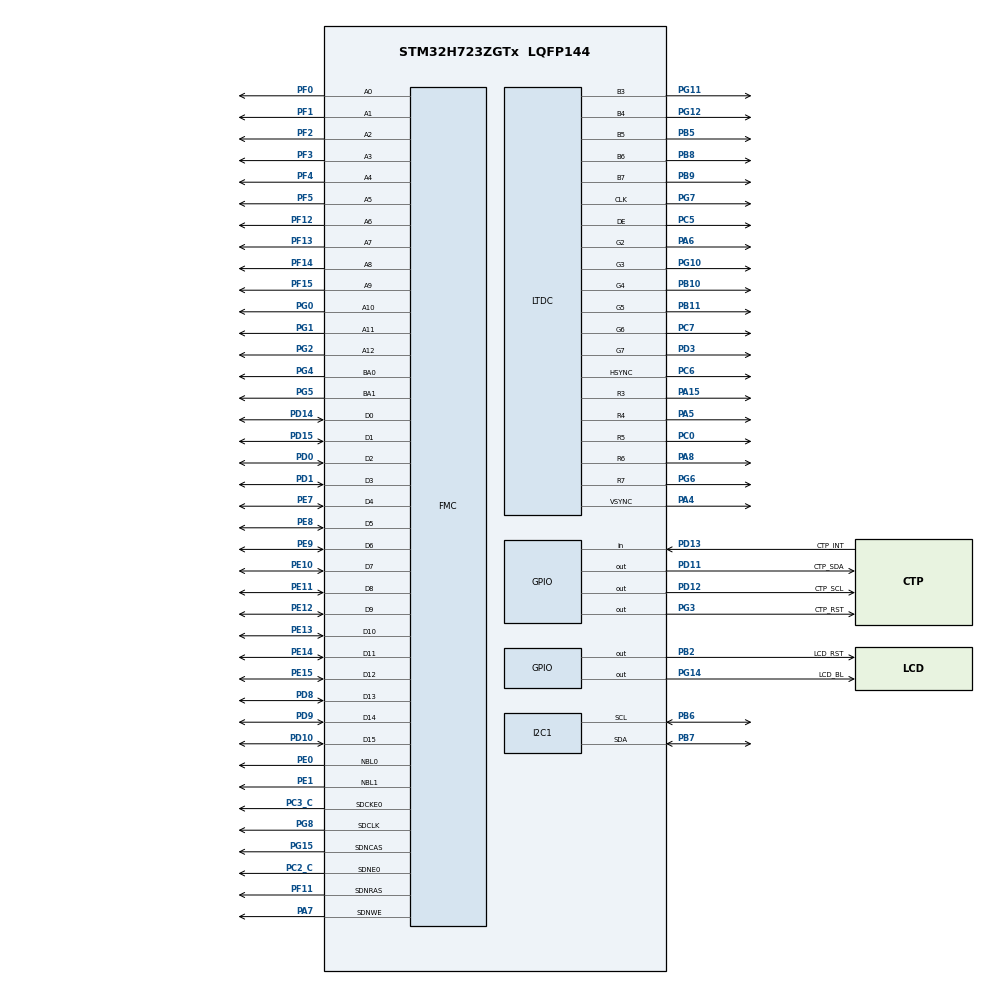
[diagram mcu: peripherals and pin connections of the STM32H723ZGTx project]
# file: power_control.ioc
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CORTEX_M7.AccessPermission-Cortex_Memory_Protection_Unit_Region0_Settings=MPU_REGION_NO_ACCESS
CORTEX_M7.AccessPermission-Cortex_Memory_Protection_Unit_Region1_Settings=MPU_REGION_FULL_ACCESS
CORTEX_M7.BaseAddress-Cortex_Memory_Protection_Unit_Region0_Settings=0x0
CORTEX_M7.BaseAddress-Cortex_Memory_Protection_Unit_Region1_Settings=0xC0000000
CORTEX_M7.DisableExec-Cortex_Memory_Protection_Unit_Region0_Settings=MPU_INSTRUCTION_ACCESS_DISABLE
CORTEX_M7.DisableExec-Cortex_Memory_Protection_Unit_Region1_Settings=MPU_INSTRUCTION_ACCESS_DISABLE
CORTEX_M7.Enable-Cortex_Memory_Protection_Unit_Region0_Settings=MPU_REGION_ENABLE
CORTEX_M7.Enable-Cortex_Memory_Protection_Unit_Region1_Settings=MPU_REGION_ENABLE
CORTEX_M7.IsBufferable-Cortex_Memory_Protection_Unit_Region0_Settings=MPU_ACCESS_NOT_BUFFERABLE
CORTEX_M7.IsBufferable-Cortex_Memory_Protection_Unit_Region1_Settings=MPU_ACCESS_NOT_BUFFERABLE
CORTEX_M7.IsCacheable-Cortex_Memory_Protection_Unit_Region0_Settings=MPU_ACCESS_NOT_CACHEABLE
CORTEX_M7.IsCacheable-Cortex_Memory_Protection_Unit_Region1_Settings=MPU_ACCESS_NOT_CACHEABLE
CORTEX_M7.IsShareable-Cortex_Memory_Protection_Unit_Region0_Settings=MPU_ACCESS_SHAREABLE
CORTEX_M7.IsShareable-Cortex_Memory_Protection_Unit_Region1_Settings=MPU_ACCESS_NOT_SHAREABLE
CORTEX_M7.MPU_Control=MPU_PRIVILEGED_DEFAULT
CORTEX_M7.Size-Cortex_Memory_Protection_Unit_Region0_Settings=MPU_REGION_SIZE_4GB
CORTEX_M7.Size-Cortex_Memory_Protection_Unit_Region1_Settings=MPU_REGION_SIZE_32MB
CORTEX_M7.SubRegionDisable-Cortex_Memory_Protection_Unit_Region0_Settings=0x87
CORTEX_M7.SubRegionDisable-Cortex_Memory_Protection_Unit_Region1_Settings=0x00
CORTEX_M7.TypeExtField-Cortex_Memory_Protection_Unit_Region0_Settings=MPU_TEX_LEVEL0
CORTEX_M7.TypeExtField-Cortex_Memory_Protection_Unit_Region1_Settings=MPU_TEX_LEVEL1
CORTEX_M7.default_mode_Activation=1
FMC.CASLatency1=FMC_SDRAM_CAS_LATENCY_2
FMC.ColumnBitsNumber1=FMC_SDRAM_COLUMN_BITS_NUM_9
FMC.ExitSelfRefreshDelay1=8
FMC.LoadToActiveDelay1=2
FMC.RCDDelay1=2
FMC.RPDelay1=2
FMC.ReadBurst1=FMC_SDRAM_RBURST_ENABLE
FMC.ReadPipeDelay1=FMC_SDRAM_RPIPE_DELAY_1
FMC.RowCycleDelay1=7
FMC.SDClockPeriod1=FMC_SDRAM_CLOCK_PERIOD_2
FMC.SelfRefreshTime1=7
FMC.WriteRecoveryTime1=5
FREERTOS.Tasks01=defaultTask,24,128,StartDefaultTask,Default,NULL,Dynamic,NULL,NULL;lcd_task,24,1024,start_lcd_task,As weak,NULL,Dynamic,NULL,NULL
FREERTOS.configRECORD_STACK_HIGH_ADDRESS=1
FREERTOS.configUSE_STATS_FORMATTING_FUNCTIONS=1
I2C1.Timing=0x60404E72
LTDC.ActiveW=800
LTDC.Alpha_L0=255
LTDC.FBStartAdress_L0=0xC0000000
LTDC.HBP=88
LTDC.HFP=40
LTDC.HSync=48
LTDC.ImageHeight_L0=480
LTDC.ImageWidth_L0=800
LTDC.Layers=0
LTDC.PixelFormat_L0=LTDC_PIXEL_FORMAT_RGB565
LTDC.VBP=32
LTDC.VFP=13
LTDC.VSync=3
LTDC.WindowX1_L0=800
LTDC.WindowY1_L0=480
Mcu.Family=STM32H7
Mcu.Name=STM32H723ZGTx
Mcu.Package=LQFP144
NVIC.PriorityGroup=NVIC_PRIORITYGROUP_4
NVIC.TIM4_IRQn=true\:15\:0\:false\:false\:true\:false\:false\:true\:true
NVIC.TimeBase=TIM4_IRQn
NVIC.TimeBaseIP=TIM4
PA13(JTMS/SWDIO).Mode=Serial_Wire
PA13(JTMS/SWDIO).Signal=DEBUG_JTMS-SWDIO
PA14(JTCK/SWCLK).Mode=Serial_Wire
PA14(JTCK/SWCLK).Signal=DEBUG_JTCK-SWCLK
PA15(JTDI).GPIO_Speed=GPIO_SPEED_FREQ_VERY_HIGH
PA15(JTDI).Mode=RGB565
PA15(JTDI).Signal=LTDC_R3
PA4.GPIO_Speed=GPIO_SPEED_FREQ_VERY_HIGH
PA4.Mode=RGB565
PA4.Signal=LTDC_VSYNC
PA5.GPIO_Speed=GPIO_SPEED_FREQ_VERY_HIGH
PA5.Mode=RGB565
PA5.Signal=LTDC_R4
PA6.GPIO_Speed=GPIO_SPEED_FREQ_VERY_HIGH
PA6.Mode=RGB565
PA6.Signal=LTDC_G2
PA7.Signal=FMC_SDNWE
PA8.GPIO_Speed=GPIO_SPEED_FREQ_VERY_HIGH
PA8.Mode=RGB565
PA8.Signal=LTDC_R6
PB10.GPIO_Speed=GPIO_SPEED_FREQ_VERY_HIGH
PB10.Mode=RGB565
PB10.Signal=LTDC_G4
PB11.GPIO_Speed=GPIO_SPEED_FREQ_VERY_HIGH
PB11.Mode=RGB565
PB11.Signal=LTDC_G5
PB2.GPIO_Label=LCD_RST
PB2.GPIO_Speed=GPIO_SPEED_FREQ_LOW
PB2.PinState=GPIO_PIN_SET
PB2.Signal=GPIO_Output
PB5.GPIO_Speed=GPIO_SPEED_FREQ_VERY_HIGH
PB5.Mode=RGB565
PB5.Signal=LTDC_B5
PB6.Mode=I2C
PB6.Signal=I2C1_SCL
PB7.Mode=I2C
PB7.Signal=I2C1_SDA
PB8.GPIO_Speed=GPIO_SPEED_FREQ_VERY_HIGH
PB8.Mode=RGB565
PB8.Signal=LTDC_B6
PB9.GPIO_Speed=GPIO_SPEED_FREQ_VERY_HIGH
PB9.Mode=RGB565
PB9.Signal=LTDC_B7
PC0.GPIO_Speed=GPIO_SPEED_FREQ_VERY_HIGH
PC0.Mode=RGB565
PC0.Signal=LTDC_R5
PC2_C.Mode=SdramChipSelect1_1
PC2_C.Signal=FMC_SDNE0
PC3_C.Mode=SdramChipSelect1_1
PC3_C.Signal=FMC_SDCKE0
PC5.GPIO_Speed=GPIO_SPEED_FREQ_VERY_HIGH
PC5.Mode=RGB565
PC5.Signal=LTDC_DE
PC6.GPIO_Speed=GPIO_SPEED_FREQ_VERY_HIGH
PC6.Mode=RGB565
PC6.Signal=LTDC_HSYNC
PC7.GPIO_Speed=GPIO_SPEED_FREQ_VERY_HIGH
PC7.Mode=RGB565
PC7.Signal=LTDC_G6
PD0.Signal=FMC_D2_DA2
PD1.Signal=FMC_D3_DA3
PD10.Signal=FMC_D15_DA15
PD11.GPIO_Label=CTP_SDA
PD11.GPIO_ModeDefaultOutputPP=GPIO_MODE_OUTPUT_OD
PD11.GPIO_PuPd=GPIO_NOPULL
PD11.GPIO_Speed=GPIO_SPEED_FREQ_VERY_HIGH
PD11.PinState=GPIO_PIN_SET
PD11.Signal=GPIO_Output
PD12.GPIO_Label=CTP_SCL
PD12.GPIO_ModeDefaultOutputPP=GPIO_MODE_OUTPUT_OD
PD12.GPIO_PuPd=GPIO_NOPULL
PD12.GPIO_Speed=GPIO_SPEED_FREQ_VERY_HIGH
PD12.PinState=GPIO_PIN_SET
PD12.Signal=GPIO_Output
PD13.GPIO_Label=CTP_INT
PD13.Signal=GPIO_Input
PD14.Signal=FMC_D0_DA0
PD15.Signal=FMC_D1_DA1
PD3.GPIO_Speed=GPIO_SPEED_FREQ_VERY_HIGH
PD3.Mode=RGB565
PD3.Signal=LTDC_G7
PD6.GPIO_Speed=GPIO_SPEED_FREQ_VERY_HIGH
PD6.Signal=LTDC_B2
PD8.Signal=FMC_D13_DA13
PD9.Signal=FMC_D14_DA14
PE0.Signal=FMC_NBL0
PE1.Signal=FMC_NBL1
PE10.Signal=FMC_D7_DA7
PE11.Signal=FMC_D8_DA8
PE12.Signal=FMC_D9_DA9
PE13.Signal=FMC_D10_DA10
PE14.Signal=FMC_D11_DA11
PE15.Signal=FMC_D12_DA12
PE7.Signal=FMC_D4_DA4
PE8.Signal=FMC_D5_DA5
PE9.Signal=FMC_D6_DA6
PF0.Signal=FMC_A0
PF1.Signal=FMC_A1
PF11.Signal=FMC_SDNRAS
PF12.Signal=FMC_A6
PF13.Signal=FMC_A7
PF14.Signal=FMC_A8
PF15.Signal=FMC_A9
PF2.Signal=FMC_A2
PF3.Signal=FMC_A3
PF4.Signal=FMC_A4
PF5.Signal=FMC_A5
PG0.Signal=FMC_A10
PG1.Signal=FMC_A11
PG10.GPIO_Speed=GPIO_SPEED_FREQ_VERY_HIGH
PG10.Mode=RGB565
PG10.Signal=LTDC_G3
PG11.GPIO_Speed=GPIO_SPEED_FREQ_VERY_HIGH
PG11.Mode=RGB565
PG11.Signal=LTDC_B3
PG12.GPIO_Speed=GPIO_SPEED_FREQ_VERY_HIGH
PG12.Mode=RGB565
PG12.Signal=LTDC_B4
PG14.GPIO_Label=LCD_BL
PG14.GPIO_Speed=GPIO_SPEED_FREQ_LOW
PG14.Signal=GPIO_Output
PG15.Signal=FMC_SDNCAS
PG2.Signal=FMC_A12
PG3.GPIO_Label=CTP_RST
PG3.GPIO_Speed=GPIO_SPEED_FREQ_VERY_HIGH
PG3.PinState=GPIO_PIN_SET
PG3.Signal=GPIO_Output
PG4.Signal=FMC_A14_BA0
PG5.Signal=FMC_A15_BA1
PG6.GPIO_Speed=GPIO_SPEED_FREQ_VERY_HIGH
PG6.Mode=RGB565
PG6.Signal=LTDC_R7
PG7.GPIO_Speed=GPIO_SPEED_FREQ_VERY_HIGH
PG7.Mode=RGB565
PG7.Signal=LTDC_CLK
PG8.Signal=FMC_SDCLK
PH0-OSC_IN.Mode=HSE-External-Oscillator
PH0-OSC_IN.Signal=RCC_OSC_IN
PH1-OSC_OUT.Mode=HSE-External-Oscillator
PH1-OSC_OUT.Signal=RCC_OSC_OUT
ProjectManager.HeapSize=0x200
ProjectManager.StackSize=0x400
ProjectManager.TargetToolchain=CMake
RCC.ADCFreq_Value=50390625
RCC.APB1Freq_Value=137500000
RCC.APB2Freq_Value=137500000
RCC.APB3Freq_Value=137500000
RCC.APB4Freq_Value=137500000
RCC.CortexFreq_Value=550000000
RCC.D1PPRE=RCC_APB3_DIV2
RCC.D2PPRE1=RCC_APB1_DIV2
RCC.D2PPRE2=RCC_APB2_DIV2
RCC.D3PPRE=RCC_APB4_DIV2
RCC.DIVM1=2
RCC.DIVM3=1
RCC.DIVN1=44
RCC.DIVN3=32
RCC.DIVP1=1
RCC.DIVR3=16
RCC.HCLKFreq_Value=275000000
RCC.HPRE=RCC_HCLK_DIV2
RCC.PLL3FRACN=0
RCC.PLLFRACN=0
RCC.PLLSourceVirtual=RCC_PLLSOURCE_HSE
RCC.SYSCLKFreq_VALUE=550000000
RCC.SYSCLKSource=RCC_SYSCLKSOURCE_PLLCLK
RCC.USBFreq_Value=275000000
SH.FMC_A0.0=FMC_A0,13b-sda1
SH.FMC_A1.0=FMC_A1,13b-sda1
SH.FMC_A10.0=FMC_A10,13b-sda1
SH.FMC_A11.0=FMC_A11,13b-sda1
SH.FMC_A12.0=FMC_A12,13b-sda1
SH.FMC_A14_BA0.0=FMC_BA0,FourSdramBanks1
SH.FMC_A15_BA1.0=FMC_BA1,FourSdramBanks1
SH.FMC_A2.0=FMC_A2,13b-sda1
SH.FMC_A3.0=FMC_A3,13b-sda1
SH.FMC_A4.0=FMC_A4,13b-sda1
SH.FMC_A5.0=FMC_A5,13b-sda1
SH.FMC_A6.0=FMC_A6,13b-sda1
SH.FMC_A7.0=FMC_A7,13b-sda1
SH.FMC_A8.0=FMC_A8,13b-sda1
SH.FMC_A9.0=FMC_A9,13b-sda1
SH.FMC_D0_DA0.0=FMC_D0,sd-16b-d1
SH.FMC_D10_DA10.0=FMC_D10,sd-16b-d1
SH.FMC_D11_DA11.0=FMC_D11,sd-16b-d1
SH.FMC_D12_DA12.0=FMC_D12,sd-16b-d1
SH.FMC_D13_DA13.0=FMC_D13,sd-16b-d1
SH.FMC_D14_DA14.0=FMC_D14,sd-16b-d1
SH.FMC_D15_DA15.0=FMC_D15,sd-16b-d1
SH.FMC_D1_DA1.0=FMC_D1,sd-16b-d1
SH.FMC_D2_DA2.0=FMC_D2,sd-16b-d1
SH.FMC_D3_DA3.0=FMC_D3,sd-16b-d1
SH.FMC_D4_DA4.0=FMC_D4,sd-16b-d1
SH.FMC_D5_DA5.0=FMC_D5,sd-16b-d1
SH.FMC_D6_DA6.0=FMC_D6,sd-16b-d1
SH.FMC_D7_DA7.0=FMC_D7,sd-16b-d1
SH.FMC_D8_DA8.0=FMC_D8,sd-16b-d1
SH.FMC_D9_DA9.0=FMC_D9,sd-16b-d1
SH.FMC_NBL0.0=FMC_NBL0,Sd2ByteEnable1
SH.FMC_NBL1.0=FMC_NBL1,Sd2ByteEnable1
SH.FMC_SDCLK.0=FMC_SDCLK,13b-sda1
SH.FMC_SDNCAS.0=FMC_SDNCAS,13b-sda1
SH.FMC_SDNRAS.0=FMC_SDNRAS,13b-sda1
SH.FMC_SDNWE.0=FMC_SDNWE,13b-sda1
VP_DMA2D_VS_DMA2D.Mode=DMA2D_Activate
VP_FREERTOS_VS_CMSIS_V2.Mode=CMSIS_V2
VP_MEMORYMAP_VS_MEMORYMAP.Mode=CurAppReg
VP_SYS_VS_tim4.Mode=TIM4
board=custom

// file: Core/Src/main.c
/* USER CODE BEGIN Header */
/**
  ******************************************************************************
  * @file           : main.c
  * @brief          : Main program body
  ******************************************************************************
  * @attention
  *
  * Copyright (c) 2026 STMicroelectronics.
  * All rights reserved.
  *
  * This software is licensed under terms that can be found in the LICENSE file
  * in the root directory of this software component.
  * If no LICENSE file comes with this software, it is provided AS-IS.
  *
  ******************************************************************************
  */
/* USER CODE END Header */
#include "main.h"
#include "FreeRTOS.h"
#include "cmsis_os2.h"
#include "dma2d.h"
#include "i2c.h"
#include "ltdc.h"
#include "gpio.h"
#include "fmc.h"

void SystemClock_Config(void);
static void MPU_Config(void);
void MX_FREERTOS_Init(void);
/* USER CODE BEGIN PFP */
static void SDRAM_MPU_Config(void);

/* USER CODE END PFP */

int main(void)
{

  /* MPU Configuration--------------------------------------------------------*/
  MPU_Config();

  /* MCU Configuration--------------------------------------------------------*/

  /* Reset of all peripherals, Initializes the Flash interface and the Systick. */
  HAL_Init();

  /* USER CODE BEGIN Init */
  SDRAM_MPU_Config();

  /* USER CODE END Init */

  /* Configure the system clock */
  SystemClock_Config();

  /* Initialize all configured peripherals */
  MX_GPIO_Init();
  MX_DMA2D_Init();
  MX_FMC_Init();
  MX_LTDC_Init();
  MX_I2C1_Init();

  /* Init scheduler */
  osKernelInitialize();  /* Call init function for freertos objects (in cmsis_os2.c) */
  MX_FREERTOS_Init();

  /* Start scheduler */
  osKernelStart();

  /* We should never get here as control is now taken by the scheduler */

  /* Infinite loop */
  while (1)
  {

  }
}

void SystemClock_Config(void)
{
  RCC_OscInitTypeDef RCC_OscInitStruct = {0};
  RCC_ClkInitTypeDef RCC_ClkInitStruct = {0};

  /** Supply configuration update enable
  */
  HAL_PWREx_ConfigSupply(PWR_LDO_SUPPLY);

  /** Configure the main internal regulator output voltage
  */
  __HAL_PWR_VOLTAGESCALING_CONFIG(PWR_REGULATOR_VOLTAGE_SCALE0);

  while(!__HAL_PWR_GET_FLAG(PWR_FLAG_VOSRDY)) {}

  /** Initializes the RCC Oscillators according to the specified parameters
  * in the RCC_OscInitTypeDef structure.
  */
  RCC_OscInitStruct.OscillatorType = RCC_OSCILLATORTYPE_HSE;
  RCC_OscInitStruct.HSEState = RCC_HSE_ON;
  RCC_OscInitStruct.PLL.PLLState = RCC_PLL_ON;
  RCC_OscInitStruct.PLL.PLLSource = RCC_PLLSOURCE_HSE;
  RCC_OscInitStruct.PLL.PLLM = 2;
  RCC_OscInitStruct.PLL.PLLN = 44;
  RCC_OscInitStruct.PLL.PLLP = 1;
  RCC_OscInitStruct.PLL.PLLQ = 2;
  RCC_OscInitStruct.PLL.PLLR = 2;
  RCC_OscInitStruct.PLL.PLLRGE = RCC_PLL1VCIRANGE_3;
  RCC_OscInitStruct.PLL.PLLVCOSEL = RCC_PLL1VCOWIDE;
  RCC_OscInitStruct.PLL.PLLFRACN = 0;
  if (HAL_RCC_OscConfig(&RCC_OscInitStruct) != HAL_OK)
  {
    Error_Handler();
  }

  /** Initializes the CPU, AHB and APB buses clocks
  */
  RCC_ClkInitStruct.ClockType = RCC_CLOCKTYPE_HCLK|RCC_CLOCKTYPE_SYSCLK
                              |RCC_CLOCKTYPE_PCLK1|RCC_CLOCKTYPE_PCLK2
                              |RCC_CLOCKTYPE_D3PCLK1|RCC_CLOCKTYPE_D1PCLK1;
  RCC_ClkInitStruct.SYSCLKSource = RCC_SYSCLKSOURCE_PLLCLK;
  RCC_ClkInitStruct.SYSCLKDivider = RCC_SYSCLK_DIV1;
  RCC_ClkInitStruct.AHBCLKDivider = RCC_HCLK_DIV2;
  RCC_ClkInitStruct.APB3CLKDivider = RCC_APB3_DIV2;
  RCC_ClkInitStruct.APB1CLKDivider = RCC_APB1_DIV2;
  RCC_ClkInitStruct.APB2CLKDivider = RCC_APB2_DIV2;
  RCC_ClkInitStruct.APB4CLKDivider = RCC_APB4_DIV2;

  if (HAL_RCC_ClockConfig(&RCC_ClkInitStruct, FLASH_LATENCY_3) != HAL_OK)
  {
    Error_Handler();
  }
}

/* USER CODE BEGIN 4 */
static void SDRAM_MPU_Config(void)
{
  MPU_Region_InitTypeDef MPU_InitStruct = {0};

  HAL_MPU_Disable();

  MPU_InitStruct.Enable = MPU_REGION_ENABLE;
  MPU_InitStruct.Number = MPU_REGION_NUMBER1;
  MPU_InitStruct.BaseAddress = 0xC0000000;
  MPU_InitStruct.Size = MPU_REGION_SIZE_32MB;
  MPU_InitStruct.SubRegionDisable = 0x00;
  MPU_InitStruct.TypeExtField = MPU_TEX_LEVEL1;
  MPU_InitStruct.AccessPermission = MPU_REGION_FULL_ACCESS;
  MPU_InitStruct.DisableExec = MPU_INSTRUCTION_ACCESS_DISABLE;
  MPU_InitStruct.IsShareable = MPU_ACCESS_NOT_SHAREABLE;
  MPU_InitStruct.IsCacheable = MPU_ACCESS_NOT_CACHEABLE;
  MPU_InitStruct.IsBufferable = MPU_ACCESS_NOT_BUFFERABLE;

  HAL_MPU_ConfigRegion(&MPU_InitStruct);
  HAL_MPU_Enable(MPU_PRIVILEGED_DEFAULT);
}

/* USER CODE END 4 */

 /* MPU Configuration */

void MPU_Config(void)
{
  MPU_Region_InitTypeDef MPU_InitStruct = {0};

  /* Disables the MPU */
  HAL_MPU_Disable();

  /** Initializes and configures the Region and the memory to be protected
  */
  MPU_InitStruct.Enable = MPU_REGION_ENABLE;
  MPU_InitStruct.Number = MPU_REGION_NUMBER0;
  MPU_InitStruct.BaseAddress = 0x0;
  MPU_InitStruct.Size = MPU_REGION_SIZE_4GB;
  MPU_InitStruct.SubRegionDisable = 0x87;
  MPU_InitStruct.TypeExtField = MPU_TEX_LEVEL0;
  MPU_InitStruct.AccessPermission = MPU_REGION_NO_ACCESS;
  MPU_InitStruct.DisableExec = MPU_INSTRUCTION_ACCESS_DISABLE;
  MPU_InitStruct.IsShareable = MPU_ACCESS_SHAREABLE;
  MPU_InitStruct.IsCacheable = MPU_ACCESS_NOT_CACHEABLE;
  MPU_InitStruct.IsBufferable = MPU_ACCESS_NOT_BUFFERABLE;

  HAL_MPU_ConfigRegion(&MPU_InitStruct);
  /* Enables the MPU */
  HAL_MPU_Enable(MPU_PRIVILEGED_DEFAULT);

}

void HAL_TIM_PeriodElapsedCallback(TIM_HandleTypeDef *htim)
{
  if (htim->Instance == TIM4)
  {
    HAL_IncTick();
  }
}

void Error_Handler(void)
{
  __disable_irq();
  while (1)
  {
  }
}

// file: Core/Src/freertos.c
/* USER CODE BEGIN Header */
/**
  ******************************************************************************
  * File Name          : freertos.c
  * Description        : Code for freertos applications
  ******************************************************************************
  * @attention
  *
  * Copyright (c) 2026 STMicroelectronics.
  * All rights reserved.
  *
  * This software is licensed under terms that can be found in the LICENSE file
  * in the root directory of this software component.
  * If no LICENSE file comes with this software, it is provided AS-IS.
  *
  ******************************************************************************
  */
/* USER CODE END Header */

#include "FreeRTOS.h"
#include "task.h"
#include "main.h"
#include "FreeRTOS.h"
#include "cmsis_os2.h"

/* USER CODE BEGIN Includes */
#include "touch_task.h"

/* USER CODE END Includes */

/* USER CODE BEGIN Variables */
static osThreadId_t touch_taskHandle;
static const osThreadAttr_t touch_task_attributes = {
  .name = "touch_task",
  .stack_size = 512 * 4,
  .priority = (osPriority_t) osPriorityAboveNormal,
};

/* USER CODE END Variables */
/* Definitions for defaultTask */
osThreadId_t defaultTaskHandle;
const osThreadAttr_t defaultTask_attributes = {
  .name = "defaultTask",
  .stack_size = 128 * 4,
  .priority = (osPriority_t) osPriorityNormal,
};
/* Definitions for lcd_task */
osThreadId_t lcd_taskHandle;
const osThreadAttr_t lcd_task_attributes = {
  .name = "lcd_task",
  .stack_size = 1024 * 4,
  .priority = (osPriority_t) osPriorityNormal,
};

/* USER CODE BEGIN FunctionPrototypes */
void start_touch_task(void *argument);

/* USER CODE END FunctionPrototypes */

void StartDefaultTask(void *argument);
void start_lcd_task(void *argument);

void MX_FREERTOS_Init(void); /* (MISRA C 2004 rule 8.1) */

void MX_FREERTOS_Init(void) {

  /* Create the thread(s) */
  /* creation of defaultTask */
  defaultTaskHandle = osThreadNew(StartDefaultTask, NULL, &defaultTask_attributes);

  /* creation of lcd_task */
  lcd_taskHandle = osThreadNew(start_lcd_task, NULL, &lcd_task_attributes);

  /* USER CODE BEGIN RTOS_THREADS */
  /* add threads, ... */
  touch_taskHandle = osThreadNew(start_touch_task, NULL, &touch_task_attributes);
  (void)touch_taskHandle;
  /* USER CODE END RTOS_THREADS */

}

void StartDefaultTask(void *argument)
{
  for(;;)
  {
    osDelay(1);
  }
}

__weak void start_lcd_task(void *argument)
{
  for(;;)
  {
    osDelay(1);
  }
}

/* USER CODE BEGIN Application */
__weak void start_touch_task(void *argument)
{
  for(;;)
  {
    osDelay(1);
  }
}

/* USER CODE END Application */
